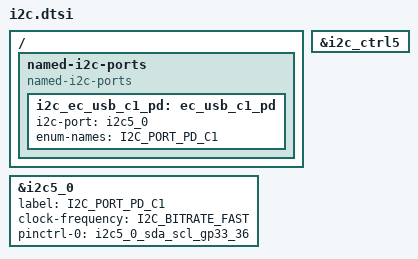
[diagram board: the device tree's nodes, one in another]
/* Copyright 2024 The ChromiumOS Authors
 * Use of this source code is governed by a BSD-style license that can be
 * found in the LICENSE file.
 */

/ {
	named-i2c-ports {
		compatible = "named-i2c-ports";

		i2c_ec_usb_c1_pd: ec_usb_c1_pd {
			i2c-port = <&i2c5_0>;
			enum-names = "I2C_PORT_PD_C1";
		};
	};
};

&i2c5_0 {
	label = "I2C_PORT_PD_C1";
	clock-frequency = <I2C_BITRATE_FAST>;
	pinctrl-0 = <&i2c5_0_sda_scl_gp33_36>;
	pinctrl-names = "default";
	status = "okay";
};

&i2c_ctrl5 {
	status = "okay";
};
